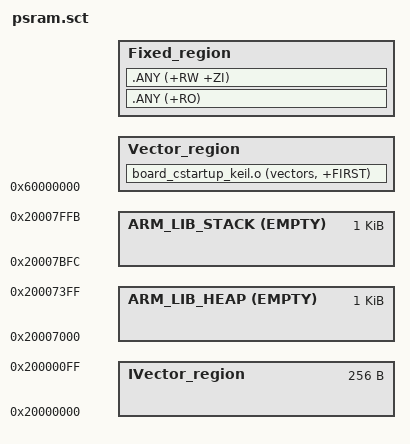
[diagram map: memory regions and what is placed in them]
; * ----------------------------------------------------------------------------
; *         ATMEL Microcontroller Software Support
; * ----------------------------------------------------------------------------
; * Copyright (c) 2008, Atmel Corporation
; *
; * All rights reserved.
; *
; * Redistribution and use in source and binary forms, with or without
; * modification, are permitted provided that the following conditions are met:
; *
; * - Redistributions of source code must retain the above copyright notice,
; * this list of conditions and the disclaimer below.
; *
; * Atmel's name may not be used to endorse or promote products derived from
; * this software without specific prior written permission.
; *
; * DISCLAIMER: THIS SOFTWARE IS PROVIDED BY ATMEL "AS IS" AND ANY EXPRESS OR
; * IMPLIED WARRANTIES, INCLUDING, BUT NOT LIMITED TO, THE IMPLIED WARRANTIES OF
; * MERCHANTABILITY, FITNESS FOR A PARTICULAR PURPOSE AND NON-INFRINGEMENT ARE
; * DISCLAIMED. IN NO EVENT SHALL ATMEL BE LIABLE FOR ANY DIRECT, INDIRECT,
; * INCIDENTAL, SPECIAL, EXEMPLARY, OR CONSEQUENTIAL DAMAGES (INCLUDING, BUT NOT
; * LIMITED TO, PROCUREMENT OF SUBSTITUTE GOODS OR SERVICES; LOSS OF USE, DATA,
; * OR PROFITS; OR BUSINESS INTERRUPTION) HOWEVER CAUSED AND ON ANY THEORY OF
; * LIABILITY, WHETHER IN CONTRACT, STRICT LIABILITY, OR TORT (INCLUDING
; * NEGLIGENCE OR OTHERWISE) ARISING IN ANY WAY OUT OF THE USE OF THIS SOFTWARE,
; * EVEN IF ADVISED OF THE POSSIBILITY OF SUCH DAMAGE.
; * ----------------------------------------------------------------------------

; *------------------------------------------------------------------------------
; *      Linker scatter for running in internal SRAM on the AT91SAM3U4
; *----------------------------------------------------------------------------*/

; /* vector is put at very begin adress of SRAM0, the preserved size is 0x100 */
Load_region 0x60000000 0x100000
{
    ; PSRAM 1M
    Vector_region 0x60000000
    {
        board_cstartup_keil.o (vectors, +FIRST)
    }

    Fixed_region +0
    {
        .ANY (+RO)
        .ANY (+RW +ZI)
    }

    ; SRAM0 32K
    IVector_region 0x20000000 0x100 {}

    ; Configure Stack and Heap
    ARM_LIB_HEAP 0x20007000 EMPTY 0x400
    {
    }

    ARM_LIB_STACK 0x20007FFC EMPTY -0x400
    {
    }
}
